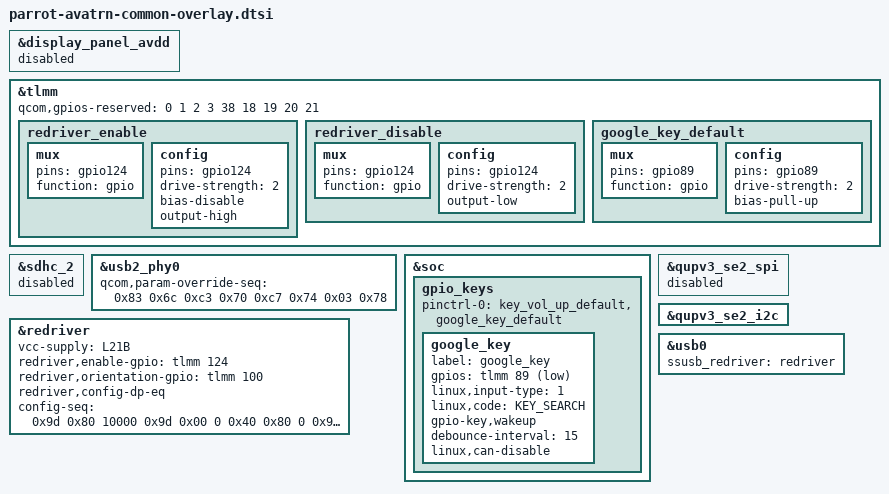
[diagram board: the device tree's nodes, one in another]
/* Copyright (c) 2021, The Linux Foundation. All rights reserved.
 *
 * This program is free software; you can redistribute it and/or modify
 * it under the terms of the GNU General Public License version 2 and
 * only version 2 as published by the Free Software Foundation.
 *
 * This program is distributed in the hope that it will be useful,
 * but WITHOUT ANY WARRANTY; without even the implied warranty of
 * MERCHANTABILITY or FITNESS FOR A PARTICULAR PURPOSE.  See the
 * GNU General Public License for more details.
 */
#include "parrot-moto-common-overlay-base-pm8350b.dtsi"
#include "parrot-moto-common-overlay.dtsi"
#include "parrot-wcn6750.dtsi"
#include "parrot-avatrn-charger-overlay.dtsi"
#include "parrot-avatrn-thermal-overlay.dtsi"
#include "parrot-avatrn-touchscreen-overlay.dtsi"
#include "parrot-avatrn-sensor-overlay.dtsi"
#include "parrot-avatrn-fps-overlay.dtsi"
#include "moto-avatrn-wl2864c.dtsi"
#include "parrot-avatrn-nfc-overlay.dtsi"
#include "parrot-avatrn-haptics-overlay.dtsi"

&display_panel_avdd {
         status = "disabled";
};

&tlmm {
	qcom,gpios-reserved = <0 1 2 3 38 18 19 20 21>;
};

&sdhc_2 {
	status = "disabled";
};

&usb2_phy0 {
	qcom,param-override-seq = <
			0x83 0x6c
			0xc3 0x70
			0xc7 0x74
			0x03 0x78>;
};

&tlmm {
	redriver_enable: redriver_enable {
		mux {
			pins = "gpio124";
			function = "gpio";
		};

		config {
			pins = "gpio124";
			drive-strength = <2>;
			bias-disable; /* NO PULL */
			output-high;
		};
	};

	redriver_disable: redriver_disable {
		mux {
			pins = "gpio124";
			function = "gpio";
		};

		config {
			pins = "gpio124";
			drive-strength = <2>;
			output-low;
		};
	};

	google_key_default: google_key_default {
		mux {
			pins = "gpio89";
			function = "gpio";
		};

		config {
			pins = "gpio89";
			drive-strength = <2>;
			bias-pull-up;
		};
	};
};

&soc {
	gpio_keys {
		pinctrl-0 = <&key_vol_up_default &google_key_default>;

		google_key {
			label = "google_key";
			gpios = <&tlmm 89 GPIO_ACTIVE_LOW>;
			linux,input-type = <1>;
			linux,code = <KEY_SEARCH>;
			gpio-key,wakeup;
			debounce-interval = <15>;
			linux,can-disable;
		};
	};
};

&qupv3_se2_spi {
	status = "disabled";
};

&qupv3_se2_i2c {
	status = "ok";
	#include "parrot-moto-common-redriver.dtsi"
};

&redriver {
	status = "ok";
	vcc-supply = <&L21B>;
	redriver,enable-gpio = <&tlmm 124 0x00>;
	redriver,orientation-gpio = <&tlmm 100 0x00>;
	redriver,config-dp-eq;
	config-seq =
		/* <reg_offset, value, delay_us> */
		<0x9d 0x80 10000
		0x9d 0x00 0
		0x40 0x80 0
		0x9f 0x02 0
		0x8d 0x01 0
		0x90 0x01 0
		0x51 0x87 0
		0x50 0x20 0
		0x54 0x11 0
		0x5d 0x66 0
		0x52 0x50 0
		0x55 0x00 0
		0x56 0x00 0
		0x57 0x00 0
		0x58 0x00 0
		0x59 0x00 0
		0x5a 0x00 0
		0x5b 0x00 0
		0x5e 0x07 0
		0x5f 0x00 0
		0x60 0x00 0
		0x61 0x03 0
		0x65 0x40 0
		0x66 0x00 0
		0x67 0x03 0
		0x75 0x0c 0
		0x77 0x00 0
		0x78 0x7c 0>;
};

&usb0 {
	ssusb_redriver = <&redriver>;
};
